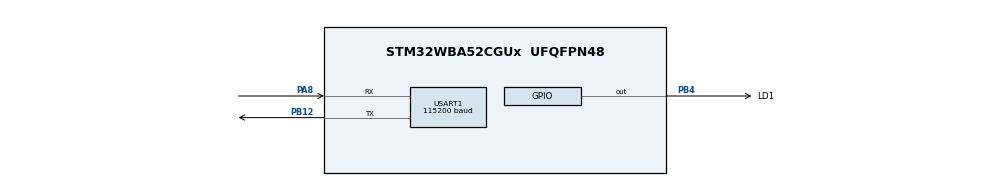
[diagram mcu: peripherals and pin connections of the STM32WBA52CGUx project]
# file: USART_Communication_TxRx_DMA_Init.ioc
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CORTEX_M33_NS.userName=CORTEX_M33
GPDMA1.DESTINC_GPDMACH2=DMA_DINC_INCREMENTED
GPDMA1.DIRECTION_GPDMACH1=DMA_MEMORY_TO_PERIPH
GPDMA1.DIRECTION_GPDMACH2=DMA_PERIPH_TO_MEMORY
GPDMA1.IPHANDLE_GPDMACH1-SIMPLEREQUEST_GPDMACH1=__NULL
GPDMA1.IPHANDLE_GPDMACH2-SIMPLEREQUEST_GPDMACH2=__NULL
GPDMA1.PRIORITY_GPDMACH1=DMA_LOW_PRIORITY_HIGH_WEIGHT
GPDMA1.PRIORITY_GPDMACH2=DMA_LOW_PRIORITY_HIGH_WEIGHT
GPDMA1.REQUEST_GPDMACH1=GPDMA1_REQUEST_USART1_TX
GPDMA1.REQUEST_GPDMACH2=GPDMA1_REQUEST_USART1_RX
GPDMA1.SRCINC_GPDMACH1=DMA_SINC_INCREMENTED
GPDMA1.SRCINC_GPDMACH2=DMA_SINC_FIXED
Mcu.Family=STM32WBA
Mcu.Name=STM32WBA52CGUx
Mcu.Package=UFQFPN48
NVIC.GPDMA1_Channel1_IRQn=true\:0\:0\:false\:false\:true\:false\:true\:true
NVIC.GPDMA1_Channel2_IRQn=true\:0\:0\:false\:false\:true\:false\:true\:true
NVIC.PriorityGroup=NVIC_PRIORITYGROUP_4
OSC_IN.Mode=HSE-External-Oscillator
OSC_IN.Signal=RCC_OSC_IN
OSC_OUT.Mode=HSE-External-Oscillator
OSC_OUT.Signal=RCC_OSC_OUT
PA8.GPIO_PuPd=GPIO_PULLDOWN
PA8.GPIO_Speed=GPIO_SPEED_FREQ_HIGH
PA8.Mode=Asynchronous
PA8.Signal=USART1_RX
PB12.GPIO_PuPd=GPIO_PULLDOWN
PB12.GPIO_Speed=GPIO_SPEED_FREQ_HIGH
PB12.Mode=Asynchronous
PB12.Signal=USART1_TX
PB4\ (NJTRST).GPIO_Label=LD1
PB4\ (NJTRST).PinState=GPIO_PIN_SET
PB4\ (NJTRST).Signal=GPIO_Output
ProjectManager.HeapSize=0x200
ProjectManager.StackSize=0x400
ProjectManager.TargetToolchain=EWARM V9.20
RCC.ADCFreq_Value=100000000
RCC.AHB5CLKDivider=DIV4
RCC.AHBFreq_Value=100000000
RCC.APB1Freq_Value=100000000
RCC.APB1TimFreq_Value=100000000
RCC.APB2Freq_Value=100000000
RCC.APB2TimFreq_Value=100000000
RCC.CortexFreq_Value=12500000
RCC.HCLKFreq_Value=100000000
RCC.HSE_VALUE=32000000
RCC.HSI_VALUE=16000000
RCC.LSE_VALUE=32768
RCC.PLLFRACN=0
RCC.PLLM=4
RCC.PLLN=25
RCC.PLLSourceVirtual=RCC_PLLSOURCE_HSE
RCC.SYSCLKFreq_VALUE=100000000
RCC.SYSCLKSourceVirtual=RCC_SYSCLKSOURCE_PLLCLK
RCC.VCOOutputFreq_Value=200000000
USART1.BaudRate=115200
USART1.ClockPrescaler=PRESCALER_DIV1
USART1.FIFOMode=FIFOMODE_DISABLE
USART1.Mode=MODE_TX_RX
USART1.Parity=PARITY_NONE
USART1.RXFIFOThreshold=RXFIFO_THRESHOLD_1EIGHTHFULL
USART1.StopBits=STOPBITS_1
USART1.TXFIFOThreshold=TXFIFO_THRESHOLD_1EIGHTHFULL
USART1.VirtualMode-Asynchronous=VM_ASYNC
USART1.WordLength=WORDLENGTH_8B
VP_GPDMA1_VS_GPDMACH1.Mode=SIMPLEREQUEST_GPDMACH1
VP_GPDMA1_VS_GPDMACH2.Mode=SIMPLEREQUEST_GPDMACH2
VP_ICACHE_VS_ICACHE.Mode=DirectMappedCache
VP_PWR_VS_SECSignals.Mode=Security/Privilege
board=custom

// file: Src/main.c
/* USER CODE BEGIN Header */
/**
  ******************************************************************************
  * @file    Examples_LL/USART/USART_Communication_TxRx_DMA_Init/Src/main.c
  * @author  MCD Application Team
  * @brief   This example describes how to send/receive bytes over USART IP using
  *          the STM32WBAxx USART LL API in DMA mode.
  *          Peripheral initialization done using LL unitary services functions.
  ******************************************************************************
  * @attention
  *
  * Copyright (c) 2023 STMicroelectronics.
  * All rights reserved.
  *
  * This software is licensed under terms that can be found in the LICENSE file
  * in the root directory of this software component.
  * If no LICENSE file comes with this software, it is provided AS-IS.
  *
  ******************************************************************************
  */
/* USER CODE END Header */
#include "main.h"

/* USER CODE BEGIN PV */

__IO uint8_t ubButtonPress = 0;

/* Buffer used for transmission */
uint8_t aTxBuffer[] = "STM32WBAxx USART LL API Example : TX/RX in DMA mode\r\nConfiguration UART 115200 bps, 8 data bit/1 stop bit/No parity/No HW flow control\r\nPlease enter 'END' string ...\r\n";
uint8_t ubNbDataToTransmit = sizeof(aTxBuffer);
__IO uint8_t ubTransmissionComplete = 0;

/* Buffer used for reception */
const uint8_t aStringToReceive[] = "END";
uint8_t ubNbDataToReceive = sizeof(aStringToReceive) - 1;
uint8_t aRxBuffer[sizeof(aStringToReceive) - 1];
__IO uint8_t ubReceptionComplete = 0;

/* USER CODE END PV */

void SystemClock_Config(void);
static void MX_GPIO_Init(void);
static void MX_GPDMA1_Init(void);
static void MX_ICACHE_Init(void);
static void MX_USART1_UART_Init(void);
/* USER CODE BEGIN PFP */

void     StartTransfers(void);
void     LED_On(void);
void     LED_Blinking(uint32_t Period);
void     LED_Off(void);
void     UserButton_Init(void);
void     WaitForUserButtonPress(void);
void     WaitAndCheckEndOfTransfer(void);
uint8_t  Buffercmp8(uint8_t *pBuffer1, uint8_t *pBuffer2, uint8_t BufferLength);

/* USER CODE END PFP */

int main(void)
{

  /* MCU Configuration--------------------------------------------------------*/

  /* Reset of all peripherals, Initializes the Flash interface and the Systick. */

  /* System interrupt init*/
  NVIC_SetPriorityGrouping(NVIC_PRIORITYGROUP_4);

  /* Enable PWR clock interface */

  LL_AHB4_GRP1_EnableClock(LL_AHB4_GRP1_PERIPH_PWR);

  /* Configure the system clock */
  SystemClock_Config();

  /* USER CODE BEGIN SysInit */
  /* Initialize USER push-button in EXTI mode */
  UserButton_Init();
  /* USER CODE END SysInit */

  /* Initialize all configured peripherals */
  MX_GPIO_Init();
  MX_GPDMA1_Init();
  MX_ICACHE_Init();
  MX_USART1_UART_Init();
  /* USER CODE BEGIN 2 */
  /* Wait for USER push-button press to start transfer */
  WaitForUserButtonPress();

  /* Initiate DMA transfers */
  StartTransfers();

  /* Wait for the end of the transfer and check received data */
  WaitAndCheckEndOfTransfer();

  /* USER CODE END 2 */

  /* Infinite loop */
  while (1)
  {

  }
}

void SystemClock_Config(void)
{
  LL_FLASH_SetLatency(LL_FLASH_LATENCY_3);
  while(LL_FLASH_GetLatency()!= LL_FLASH_LATENCY_3)
  {
  }

  LL_PWR_SetRegulVoltageScaling(LL_PWR_REGU_VOLTAGE_SCALE1);
  LL_RCC_HSE_Enable();

   /* Wait till HSE is ready */
  while(LL_RCC_HSE_IsReady() != 1)
  {
  }

  LL_RCC_PLL1_ConfigDomain_SYS(LL_RCC_PLL1SOURCE_HSE, 4, 25, 2);
  LL_RCC_PLL1_EnableDomain_PLL1R();
  LL_RCC_PLL1_SetVCOInputRange(LL_RCC_PLLINPUTRANGE_8_16);
  LL_RCC_PLL1_Enable();

   /* Wait till PLL is ready */
  while(LL_RCC_PLL1_IsReady() != 1)
  {
  }

  LL_RCC_SetSysClkSource(LL_RCC_SYS_CLKSOURCE_PLL1R);

   /* Wait till System clock is ready */
  while(LL_RCC_GetSysClkSource() != LL_RCC_SYS_CLKSOURCE_STATUS_PLL1R)
  {
  }

  LL_RCC_SetAHBPrescaler(LL_RCC_SYSCLK_DIV_1);
  LL_RCC_SetAHB5Prescaler(LL_RCC_AHB5_DIV_4);
  LL_RCC_SetAPB1Prescaler(LL_RCC_APB1_DIV_1);
  LL_RCC_SetAPB2Prescaler(LL_RCC_APB2_DIV_1);
  LL_RCC_SetAPB7Prescaler(LL_RCC_APB7_DIV_1);

  LL_Init1msTick(100000000);

  LL_SetSystemCoreClock(100000000);
}

static void MX_GPDMA1_Init(void)
{

  /* Peripheral clock enable */
  LL_AHB1_GRP1_EnableClock(LL_AHB1_GRP1_PERIPH_GPDMA1);

  /* GPDMA1 interrupt Init */
  NVIC_SetPriority(GPDMA1_Channel1_IRQn, NVIC_EncodePriority(NVIC_GetPriorityGrouping(),0, 0));
  NVIC_EnableIRQ(GPDMA1_Channel1_IRQn);
  NVIC_SetPriority(GPDMA1_Channel2_IRQn, NVIC_EncodePriority(NVIC_GetPriorityGrouping(),0, 0));
  NVIC_EnableIRQ(GPDMA1_Channel2_IRQn);

}

static void MX_ICACHE_Init(void)
{

  /** Enable instruction cache in 1-way (direct mapped cache)
  */
  LL_ICACHE_SetMode(LL_ICACHE_1WAY);
  LL_ICACHE_Enable();

}

static void MX_USART1_UART_Init(void)
{

  LL_USART_InitTypeDef USART_InitStruct = {0};

  LL_GPIO_InitTypeDef GPIO_InitStruct = {0};
  LL_DMA_InitTypeDef DMA_InitStruct = {0};

  LL_RCC_SetUSARTClockSource(LL_RCC_USART1_CLKSOURCE_PCLK2);

  /* Peripheral clock enable */
  LL_APB2_GRP1_EnableClock(LL_APB2_GRP1_PERIPH_USART1);

  LL_AHB2_GRP1_EnableClock(LL_AHB2_GRP1_PERIPH_GPIOB);
  LL_AHB2_GRP1_EnableClock(LL_AHB2_GRP1_PERIPH_GPIOA);
  /**USART1 GPIO Configuration
  PB12   ------> USART1_TX
  PA8   ------> USART1_RX
  */
  GPIO_InitStruct.Pin = LL_GPIO_PIN_12;
  GPIO_InitStruct.Mode = LL_GPIO_MODE_ALTERNATE;
  GPIO_InitStruct.Speed = LL_GPIO_SPEED_FREQ_HIGH;
  GPIO_InitStruct.OutputType = LL_GPIO_OUTPUT_PUSHPULL;
  GPIO_InitStruct.Pull = LL_GPIO_PULL_DOWN;
  GPIO_InitStruct.Alternate = LL_GPIO_AF_7;
  LL_GPIO_Init(GPIOB, &GPIO_InitStruct);

  GPIO_InitStruct.Pin = LL_GPIO_PIN_8;
  GPIO_InitStruct.Mode = LL_GPIO_MODE_ALTERNATE;
  GPIO_InitStruct.Speed = LL_GPIO_SPEED_FREQ_HIGH;
  GPIO_InitStruct.OutputType = LL_GPIO_OUTPUT_PUSHPULL;
  GPIO_InitStruct.Pull = LL_GPIO_PULL_DOWN;
  GPIO_InitStruct.Alternate = LL_GPIO_AF_7;
  LL_GPIO_Init(GPIOA, &GPIO_InitStruct);

  /* USART1 DMA Init */

  /* GPDMA1_REQUEST_USART1_RX Init */
  DMA_InitStruct.SrcAddress = 0x00000000U;
  DMA_InitStruct.DestAddress = 0x00000000U;
  DMA_InitStruct.Direction = LL_DMA_DIRECTION_PERIPH_TO_MEMORY;
  DMA_InitStruct.BlkHWRequest = LL_DMA_HWREQUEST_SINGLEBURST;
  DMA_InitStruct.DataAlignment = LL_DMA_DATA_ALIGN_ZEROPADD;
  DMA_InitStruct.SrcBurstLength = 1;
  DMA_InitStruct.DestBurstLength = 1;
  DMA_InitStruct.SrcDataWidth = LL_DMA_SRC_DATAWIDTH_BYTE;
  DMA_InitStruct.DestDataWidth = LL_DMA_DEST_DATAWIDTH_BYTE;
  DMA_InitStruct.SrcIncMode = LL_DMA_SRC_FIXED;
  DMA_InitStruct.DestIncMode = LL_DMA_DEST_INCREMENT;
  DMA_InitStruct.Priority = LL_DMA_LOW_PRIORITY_HIGH_WEIGHT;
  DMA_InitStruct.BlkDataLength = 0x00000000U;
  DMA_InitStruct.TriggerMode = LL_DMA_TRIGM_BLK_TRANSFER;
  DMA_InitStruct.TriggerPolarity = LL_DMA_TRIG_POLARITY_MASKED;
  DMA_InitStruct.TriggerSelection = 0x00000000U;
  DMA_InitStruct.Request = LL_GPDMA1_REQUEST_USART1_RX;
  DMA_InitStruct.TransferEventMode = LL_DMA_TCEM_BLK_TRANSFER;
  DMA_InitStruct.SrcAllocatedPort = LL_DMA_SRC_ALLOCATED_PORT0;
  DMA_InitStruct.DestAllocatedPort = LL_DMA_DEST_ALLOCATED_PORT0;
  DMA_InitStruct.LinkAllocatedPort = LL_DMA_LINK_ALLOCATED_PORT1;
  DMA_InitStruct.LinkStepMode = LL_DMA_LSM_FULL_EXECUTION;
  DMA_InitStruct.LinkedListBaseAddr = 0x00000000U;
  DMA_InitStruct.LinkedListAddrOffset = 0x00000000U;
  LL_DMA_Init(GPDMA1, LL_DMA_CHANNEL_2, &DMA_InitStruct);

  /* GPDMA1_REQUEST_USART1_TX Init */
  DMA_InitStruct.SrcAddress = 0x00000000U;
  DMA_InitStruct.DestAddress = 0x00000000U;
  DMA_InitStruct.Direction = LL_DMA_DIRECTION_MEMORY_TO_PERIPH;
  DMA_InitStruct.BlkHWRequest = LL_DMA_HWREQUEST_SINGLEBURST;
  DMA_InitStruct.DataAlignment = LL_DMA_DATA_ALIGN_ZEROPADD;
  DMA_InitStruct.SrcBurstLength = 1;
  DMA_InitStruct.DestBurstLength = 1;
  DMA_InitStruct.SrcDataWidth = LL_DMA_SRC_DATAWIDTH_BYTE;
  DMA_InitStruct.DestDataWidth = LL_DMA_DEST_DATAWIDTH_BYTE;
  DMA_InitStruct.SrcIncMode = LL_DMA_SRC_INCREMENT;
  DMA_InitStruct.DestIncMode = LL_DMA_DEST_FIXED;
  DMA_InitStruct.Priority = LL_DMA_LOW_PRIORITY_HIGH_WEIGHT;
  DMA_InitStruct.BlkDataLength = 0x00000000U;
  DMA_InitStruct.TriggerMode = LL_DMA_TRIGM_BLK_TRANSFER;
  DMA_InitStruct.TriggerPolarity = LL_DMA_TRIG_POLARITY_MASKED;
  DMA_InitStruct.TriggerSelection = 0x00000000U;
  DMA_InitStruct.Request = LL_GPDMA1_REQUEST_USART1_TX;
  DMA_InitStruct.TransferEventMode = LL_DMA_TCEM_BLK_TRANSFER;
  DMA_InitStruct.SrcAllocatedPort = LL_DMA_SRC_ALLOCATED_PORT0;
  DMA_InitStruct.DestAllocatedPort = LL_DMA_DEST_ALLOCATED_PORT0;
  DMA_InitStruct.LinkAllocatedPort = LL_DMA_LINK_ALLOCATED_PORT1;
  DMA_InitStruct.LinkStepMode = LL_DMA_LSM_FULL_EXECUTION;
  DMA_InitStruct.LinkedListBaseAddr = 0x00000000U;
  DMA_InitStruct.LinkedListAddrOffset = 0x00000000U;
  LL_DMA_Init(GPDMA1, LL_DMA_CHANNEL_1, &DMA_InitStruct);

  /* USER CODE BEGIN USART1_Init 1 */
  /* Configure the DMA functional parameters for transmission */
  LL_DMA_ConfigAddresses(GPDMA1, LL_DMA_CHANNEL_1,
                         (uint32_t)aTxBuffer,
                         LL_USART_DMA_GetRegAddr(USART1, LL_USART_DMA_REG_DATA_TRANSMIT));
  LL_DMA_SetBlkDataLength(GPDMA1, LL_DMA_CHANNEL_1, ubNbDataToTransmit);

  /* Configure the DMA functional parameters for reception */
  LL_DMA_ConfigAddresses(GPDMA1, LL_DMA_CHANNEL_2,
                         LL_USART_DMA_GetRegAddr(USART1, LL_USART_DMA_REG_DATA_RECEIVE),
                         (uint32_t)aRxBuffer);
  LL_DMA_SetBlkDataLength(GPDMA1, LL_DMA_CHANNEL_2, ubNbDataToReceive);

  /* Enable DMA transfer complete/error interrupts  */
  LL_DMA_EnableIT_TC(GPDMA1, LL_DMA_CHANNEL_1);
  LL_DMA_EnableIT_DTE(GPDMA1, LL_DMA_CHANNEL_1);
  LL_DMA_EnableIT_TC(GPDMA1, LL_DMA_CHANNEL_2);
  LL_DMA_EnableIT_DTE(GPDMA1, LL_DMA_CHANNEL_2);
  /* USER CODE END USART1_Init 1 */
  USART_InitStruct.PrescalerValue = LL_USART_PRESCALER_DIV1;
  USART_InitStruct.BaudRate = 115200;
  USART_InitStruct.DataWidth = LL_USART_DATAWIDTH_8B;
  USART_InitStruct.StopBits = LL_USART_STOPBITS_1;
  USART_InitStruct.Parity = LL_USART_PARITY_NONE;
  USART_InitStruct.TransferDirection = LL_USART_DIRECTION_TX_RX;
  USART_InitStruct.HardwareFlowControl = LL_USART_HWCONTROL_NONE;
  USART_InitStruct.OverSampling = LL_USART_OVERSAMPLING_16;
  LL_USART_Init(USART1, &USART_InitStruct);
  LL_USART_SetTXFIFOThreshold(USART1, LL_USART_FIFOTHRESHOLD_1_8);
  LL_USART_SetRXFIFOThreshold(USART1, LL_USART_FIFOTHRESHOLD_1_8);
  LL_USART_DisableFIFO(USART1);
  LL_USART_ConfigAsyncMode(USART1);
  LL_USART_Enable(USART1);
  /* USER CODE BEGIN USART1_Init 2 */

  /* Polling USART initialisation */
  while ((!(LL_USART_IsActiveFlag_TEACK(USART1))) || (!(LL_USART_IsActiveFlag_REACK(USART1))))
  {
  }
  /* USER CODE END USART1_Init 2 */

}

static void MX_GPIO_Init(void)
{
  LL_GPIO_InitTypeDef GPIO_InitStruct = {0};

  /* GPIO Ports Clock Enable */
  LL_AHB2_GRP1_EnableClock(LL_AHB2_GRP1_PERIPH_GPIOB);
  LL_AHB2_GRP1_EnableClock(LL_AHB2_GRP1_PERIPH_GPIOA);

  /**/
  LL_GPIO_SetOutputPin(LD1_GPIO_Port, LD1_Pin);

  /**/
  GPIO_InitStruct.Pin = LD1_Pin;
  GPIO_InitStruct.Mode = LL_GPIO_MODE_OUTPUT;
  GPIO_InitStruct.Speed = LL_GPIO_SPEED_FREQ_LOW;
  GPIO_InitStruct.OutputType = LL_GPIO_OUTPUT_PUSHPULL;
  GPIO_InitStruct.Pull = LL_GPIO_PULL_NO;
  LL_GPIO_Init(LD1_GPIO_Port, &GPIO_InitStruct);

}

/* USER CODE BEGIN 4 */

/**
  * @brief  This function initiates TX and RX DMA transfers by enabling DMA channels
  * @param  None
  * @retval None
  */
void StartTransfers(void)
{
  /* Enable DMA RX Interrupt */
  LL_USART_EnableDMAReq_RX(USART1);

  /* Enable DMA TX Interrupt */
  LL_USART_EnableDMAReq_TX(USART1);

  /* Enable DMA Channel Rx */
  LL_DMA_EnableChannel(GPDMA1, LL_DMA_CHANNEL_2);

  /* Enable DMA Channel Tx */
  LL_DMA_EnableChannel(GPDMA1, LL_DMA_CHANNEL_1);
}

/**
  * @brief  Turn-on LD1.
  * @param  None
  * @retval None
  */
void LED_On(void)
{
  /* Turn LD1 on */
  LL_GPIO_ResetOutputPin(LD1_GPIO_Port, LD1_Pin);
}

/**
  * @brief  Turn-off LD1.
  * @param  None
  * @retval None
  */
void LED_Off(void)
{
  /* Turn LD1 off */
  LL_GPIO_SetOutputPin(LD1_GPIO_Port, LD1_Pin);
}

/**
  * @brief  Set LD1 to Blinking mode for an infinite loop (toggle period based on value provided as input parameter).
  * @param  Period : Period of time (in ms) between each toggling of LED
  *   This parameter can be user defined values. Pre-defined values used in that example are :
  *     @arg LED_BLINK_FAST : Fast Blinking
  *     @arg LED_BLINK_SLOW : Slow Blinking
  *     @arg LED_BLINK_ERROR : Error specific Blinking
  * @retval None
  */
void LED_Blinking(uint32_t Period)
{
  /* Toggle LD1 in an infinite loop */
  while (1)
  {
    LL_GPIO_TogglePin(LD1_GPIO_Port, LD1_Pin);
    LL_mDelay(Period);
  }
}

/**
  * @brief  Configures USER push-button in GPIO or EXTI Line Mode.
  * @param  None
  * @retval None
  */
void UserButton_Init(void)
{
  /* Enable the BUTTON Clock */
  USER_BUTTON_GPIO_CLK_ENABLE();

  /* Configure GPIO for BUTTON */
  LL_GPIO_SetPinMode(USER_BUTTON_GPIO_PORT, USER_BUTTON_PIN, LL_GPIO_MODE_INPUT);
  LL_GPIO_SetPinPull(USER_BUTTON_GPIO_PORT, USER_BUTTON_PIN, LL_GPIO_PULL_UP);

  /* Connect External Line to the GPIO*/
  USER_BUTTON_SYSCFG_SET_EXTI();

  /* Enable a rising trigger External line 13 Interrupt */
  USER_BUTTON_EXTI_LINE_ENABLE();
  USER_BUTTON_EXTI_FALLING_TRIG_ENABLE();

  /* Configure NVIC for USER_BUTTON_EXTI_IRQn */
  NVIC_SetPriority(USER_BUTTON_EXTI_IRQn, 3);
  NVIC_EnableIRQ(USER_BUTTON_EXTI_IRQn);
}

/**
  * @brief  Wait for USER push-button press to start transfer.
  * @param  None
  * @retval None
  */
/*  */
void WaitForUserButtonPress(void)
{
  while (ubButtonPress == 0)
  {
    LL_GPIO_TogglePin(LD1_GPIO_Port, LD1_Pin);
    LL_mDelay(LED_BLINK_FAST);
  }
  /* Ensure that LD1 is turned Off */
  LED_Off();
}

/**
  * @brief  Wait end of transfer and check if received Data are well.
  * @param  None
  * @retval None
  */
void WaitAndCheckEndOfTransfer(void)
{
  /* 1 - Wait end of transmission */
  while (ubTransmissionComplete != 1)
  {
  }
  /* Disable GPDMA1 Tx Channel */
  LL_DMA_DisableChannel(GPDMA1, LL_DMA_CHANNEL_1);

  /* 2 - Wait end of reception */
  while (ubReceptionComplete != 1)
  {
  }
  /* Disable GPDMA1 Rx Channel */
  LL_DMA_DisableChannel(GPDMA1, LL_DMA_CHANNEL_2);

  /* 3 - Compare received string to expected one */
  if (Buffercmp8((uint8_t *)aStringToReceive, (uint8_t *)aRxBuffer, ubNbDataToReceive))
  {
    /* Processing Error */
    LED_Blinking(LED_BLINK_ERROR);
  }
  else
  {
    /* Turn On Led if data are well received */
    LED_On();
  }
}

/**
* @brief Compares two 8-bit buffers and returns the comparison result.
* @param pBuffer1: pointer to the source buffer to be compared to.
* @param pBuffer2: pointer to the second source buffer to be compared to the first.
* @param BufferLength: buffer's length.
* @retval   0: Comparison is OK (the two Buffers are identical)
*           Value different from 0: Comparison is NOK (Buffers are different)
*/
uint8_t Buffercmp8(uint8_t *pBuffer1, uint8_t *pBuffer2, uint8_t BufferLength)
{
  while (BufferLength--)
  {
    if (*pBuffer1 != *pBuffer2)
    {
      return 1;
    }

    pBuffer1++;
    pBuffer2++;
  }

  return 0;
}

/******************************************************************************/
/*   USER IRQ HANDLER TREATMENT Functions                                     */
/******************************************************************************/
/**
  * @brief  Function to manage USER push-button
  * @param  None
  * @retval None
  */
void UserButton_Callback(void)
{
  /* Update USER push-button variable : to be checked in waiting loop in main program */
  ubButtonPress = 1;
}

/**
  * @brief  Function called from GPDMA1 IRQ Handler when Tx transfer is completed
  * @param  None
  * @retval None
  */
void GPDMA1_TransmitComplete_Callback(void)
{
  /* DMA Tx transfer completed */
  ubTransmissionComplete = 1;
}

/**
  * @brief  Function called from GPDMA1 IRQ Handler when Rx transfer is completed
  * @param  None
  * @retval None
  */
void GPDMA1_ReceiveComplete_Callback(void)
{
  /* DMA Rx transfer completed */
  ubReceptionComplete = 1;
}

/**
  * @brief  Function called in case of error detected in USART IT Handler
  * @param  None
  * @retval None
  */
void USART_TransferError_Callback(void)
{
  /* Disable GPDMA1 Tx Channel */
  LL_DMA_DisableChannel(GPDMA1, LL_DMA_CHANNEL_1);

  /* Disable GPDMA1 Rx Channel */
  LL_DMA_DisableChannel(GPDMA1, LL_DMA_CHANNEL_2);

  /* Set LD1 to Blinking mode to indicate error occurs */
  LED_Blinking(LED_BLINK_ERROR);
}

/* USER CODE END 4 */

void Error_Handler(void)
{
}
